# ESM_ESM_52D00000h register map
Vendor: Texas Instruments
Peripheral module from a debugger description file (folder AM261x).
Registers are 32-bit, read-write, reset 0x0 unless marked. A register's access mark holds for its fields unless they carry their own. Offsets are as the file gives them; lines under a group give offsets from that group; [hi:lo] are bit positions; {n}, {i} and the like mark numbered series; 'fields as' and 'values as' point back to an identical list; <NAME> marks a mode.

## ESM
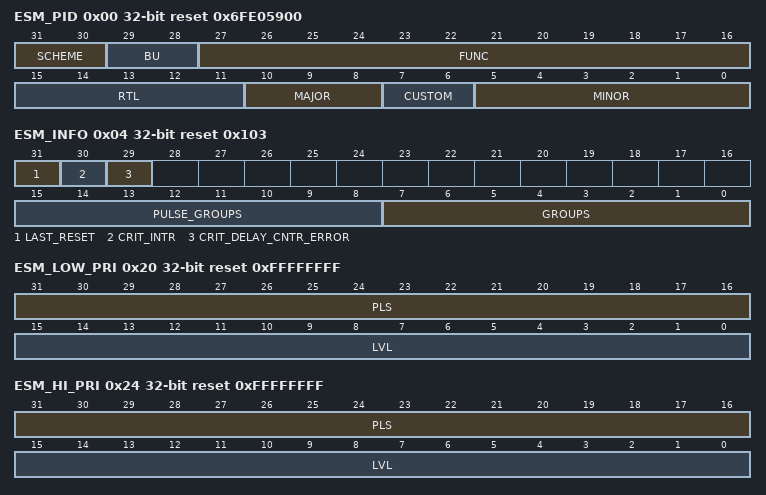
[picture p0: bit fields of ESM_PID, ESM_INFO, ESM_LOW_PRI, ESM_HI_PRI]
0x00 ESM_PID ro reset 0x6FE05900 — The Revision Register contains the major and minor revisions for the module.
  [31:30] SCHEME — PID register scheme
  [29:28] BU — Business Unit: 10 = Processors
  [27:16] FUNC — Module ID
  [15:11] RTL — RTL revision. Will vary depending on release.
  [10:8] MAJOR — Major revision
  [7:6] CUSTOM
  [5:0] MINOR — Minor revision
0x04 ESM_INFO ro reset 0x103 — The Info Register gives the configuration Inforrmation of this ESM.
  [31] LAST_RESET — Indicates the Source of the last Reset
  [30] CRIT_INTR — Indicates if the critical priority interrupt output has asserted
  [29] CRIT_DELAY_CNTR_ERROR — Indicates if a bit error has occurred in the critical priority interrupt delay counter
  [15:8] PULSE_GROUPS — Number of Pulse Error Groups
  [7:0] GROUPS — Total number of Error Groups
0x08 ESM_EN — The Global Enable Register has the master interrupt mask.
  [3:0] KEY — Global Enable
0x0C ESM_SFT_RST wo — The Global Soft Reset Register controls the global clear for raw status and enables.
  [3:0] KEY — Global Soft Reset
0x10 ESM_ERR_RAW access not given — Raw Status/Set Register for Configuration Errors.
  [2:0] STS — This is the raw status for config errors (access R/W1TS)
0x14 ESM_ERR_STS access not given — Config Error Enable and Clear Register.
  [2:0] MSK — This is the masked status/clear for config errors (access R/W1TC)
0x18 ESM_ERR_EN_SET access not given — Config Error Enable Set Register.
  [2:0] MSK — This is the mask enable set for config errors (access R/W1TS)
0x1C ESM_ERR_EN_CLR access not given — Config Error Interrupt Enabled Clear register.
  [2:0] MSK — This is the mask enable clear for config errors (access R/W1TC)
0x20 ESM_LOW_PRI ro reset 0xFFFFFFFF — Shows which is the highest priority outstanding low priority interrupt.
  [31:16] PLS — This is the highest priority outstanding low priority pulse interrupt
  [15:0] LVL — This is the highest priority outstanding low priority level interrupt
0x24 ESM_HI_PRI ro reset 0xFFFFFFFF — Shows which is the highest priority outstanding high priority interrupt.
  [31:16] PLS — This is the highest priority outstanding high priority pulse interrupt
  [15:0] LVL — This is the highest priority outstanding high priority level interrupt
0x28 ESM_LOW ro — Shows which groups have oustanding low priority interrupts.
  [31:0] STS — This is the raw status for config errors
0x2C ESM_HI ro — Shows which groups have oustanding high priority interrupts.
  [31:0] STS — This is the raw status for config errors
0x30 ESM_EOI wo — End of Interrupt Register.
  [10:0] KEY — This is the interrupt being serviced
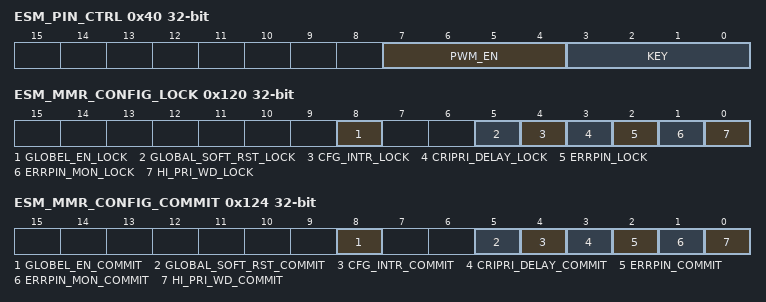
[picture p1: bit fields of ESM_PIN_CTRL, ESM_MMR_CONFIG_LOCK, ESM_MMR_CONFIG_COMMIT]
0x40 ESM_PIN_CTRL — This register controls the error_pin_n output.
  [7:4] PWM_EN — PWM enable
  [3:0] KEY — Pin Control Key
0x44 ESM_PIN_STS ro — This register reflects the status of the error_pin_n output.
  [0] VAL — Value of the error_pin_n
0x48 ESM_PIN_CNTR ro — This register shows the current value of the error pin counter.
  [23:0] COUNT — Current Counter Value
0x4C ESM_PIN_CNTR_PRE — This register contains the value that is loaded in to the Error Counter.
  [23:0] COUNT — Counter Pre-Load Value
0x50 ESM_PWMH_PIN_CNTR ro — This register shows the current value of the error pin PWM high counter.
  [23:0] COUNT — Current Counter Value
0x54 ESM_PWMH_PIN_CNTR_PRE — This register contains the value that is loaded in to the Error PWM High Counter.
  [23:0] COUNT — Counter Pre-Load Value
0x58 ESM_PWML_PIN_CNTR ro — This register shows the current value of the error pin PWM low counter.
  [23:0] COUNT — Current Counter Value
0x5C ESM_PWML_PIN_CNTR_PRE — This register contains the value that is loaded in to the Error PWM Low Counter.
  [23:0] COUNT — Counter Pre-Load Value
0x60 ESM_CRIT_DELAY_CNTR ro — This register shows the current value of the Critical Priority Interrupt Delay Counter.
  [31:0] COUNT — Current Counter Value
0x64 ESM_CRIT_DELAY_CNTR_PRE — This register contains the value that is loaded into the Critical Priority Interrupt Delay Counter.
  [31:0] COUNT — Counter Pre-Load Value
0x80 ESM_HI_PRI_WD_CFG — The High Priority Watchdog Config Register is used to enable or disable the High Priority Watchdog and its associated interrupt.
  [3:0] WD_EN — Enable field for the High Priority Watchdog. 0xA Enables the watchdog. All other values disable the watchdog
0x84 ESM_HI_PRI_WD_CNTR ro — The High Priority Watchdog Counter Register reflects the current value of the High Priority Watchdog Counter. When enabled, this counter will start decrementing (from the High Priority Pre-Load value) as soon as any of the enabled Errors associated with the High Priority Interrupt is active. This counter is reset by the warm reset.
  [31:0] COUNT — Current Counter Value
0x88 ESM_HI_PRI_WD_CNTR_PRE — The High Priority Watchdog Pre-Load Register reflects the value that is loaded into the High Priority Watchdog Counter Register.
  [31:0] COUNT — Counter Pre-Load Value
0x8C ESM_HI_PRI_WD_INTR_SET access not given — The High Priority Watchdog Status/Set Register indicates the status of the High Priority Watchdog Interrupt. This register is reset by the Power On Reset. A write to this register may allow software to set the interrupt output.
  [0] VAL — Read the current interrupt status. Write 1 to set the interrupt output (access R/W1TS)
0x90 ESM_HI_PRI_WD_INTR_CLR access not given — The High Priority Watchdog Status/Clear Register indicates the status of the High Priority Watchdog Interrupt. This register is reset by the Power On Reset. A write to this register may allow software to temporarily clear the interrupt.
  [0] VAL — Read the current interrupt status. Write 1 to clear the interrupt output. The interrupt will reassert if the conditions that triggered it persist (access R/W1TC)
0xA0 ESM_ERRPIN_MON_CFG — The Error Pin Monitor Config Register is used to enable or disable the Error Pin Monitor and its associated interrupt.
  [3:0] MON_EN — Enable field for the Error Pin Monitor. 0xA Enables the monitor. All other values disable the monitor
0xA4 ESM_ERRPIN_MON_INTR_SET access not given — The Error Pin Monitor Interrupt Status/Set Register indicates the status of the Error Pin Monitor Interrupt. This register is reset by the Power On Reset. A write to this register may allow software to set the interrupt output.
  fields as ESM_HI_PRI_WD_INTR_SET
0xA8 ESM_ERRPIN_MON_INTR_CLR access not given — The Error Pin Monitor Status/Clear Register indicates the status of the Error Pin Monitor Interrupt. This register is reset by the Power On Reset. A write to this register may allow software to temporarily clear the interrupt.
  fields as ESM_HI_PRI_WD_INTR_CLR
0x100 ESM_GROUP_N_LOCK — The fields of the Group N Interrupt Lock Register lock the configuration for the associated Error Group N Interrupt Enable Set/Clear Registers and the Error Group N Interrupt Priority Register. This locks the associated enable and priority bits for each Group for Low and High Priority Interrupts. Locks may be written until the associated Commit MMR fields are set to 1. Once Lock is 1 and Commit is 1, the associated configuration may not be changed until reset.
  [31:0] LOCK — Each bit lock[N] bit will lock the associated masking MMRs associated with Group N. These are: Error Group N Interrupt Enabled Set Register, Error Group N Interrupt Enabled Clear Register, Error Group N Interrupt Priority Register
0x104 ESM_GROUP_N_COMMIT — The fields of the Group N Interrupt Commit Register commit the lock configuration for the associated Group N Interrupt Lock Register. This prevents the Locks in the Group N Interrupt Lock Register from changing. Once Commit is 1, the associated Lock and Commit may not be changed until reset.
  [31:0] COMMIT — Each bit commit[N] bit will commit the lock configuration for the corresponding bit in the Group N Interrupt Lock Register.
0x110 ESM_ERR_PIN_INFLUENCE_LOCK — The fields of the Error Pin Influence Lock Register lock the Error Pin Influence configuration for the associated Error Groups. Locks may be written until the associated Commit MMR fields are set to 1. Once Lock is 1 and Commit is 1, the associated configuration may not be changed until reset.
  [31:0] LOCK — Each bit lock[N] bit will lock the associated masking MMRs associated with Group N. These are: Error Group N Error Pin Influence Set Register, Error Group N Error Pin Influence Clear Register
0x114 ESM_ERR_PIN_INFLUENCE_COMMIT — The fields of the Error Pin Influence Commit Register commit the lock configuration for the associated Error Groups. This prevents the Locks in the Error Pin Influence Lock Register from changing. Once Commit is 1, the associated Lock and Commit may not be changed until reset.
  [31:0] COMMIT — Each bit commit[N] bit will commit the lock configuration for the corresponding bit in the Error Pin Influence Lock Register.
0x118 ESM_CRI_PRI_INFLUENCE_LOCK — The fields of the Critical Priority Interrupt Influence Lock Register lock the Critical Priority Interrupt Influence configuration for the associated Error Groups. Locks may be written until the associated Commit MMR fields are set to 1. Once Lock is 1 and Commit is 1, the associated configuration may not be changed until reset.
  [31:0] LOCK — Each bit lock[N] bit will lock the associated masking MMRs associated with Group N. These are: Error Group N Critical Priority Interrupt Influence Set Register, Error Group N Critical Priority Interrupt Influence Clear Register
0x11C ESM_CRI_PRI_INFLUENCE_COMMIT — The fields of the Critical Priority Interrupt Influence Commit Register commit the lock configuration for the associated Error Groups. This prevents the Locks in the Critical Priority Interrupt Influence Lock Register from changing. Once Commit is 1, the associated Lock and Commit may not be changed until reset.
  [31:0] COMMIT — Each bit commit[N] bit will commit the lock configuration for the corresponding bit in the Critical Priority Interrupt Influence Lock Register.
0x120 ESM_MMR_CONFIG_LOCK — The fields of the MMR Config Lock Register lock the configuration for the associated MMRs. This prevents changes once the lock configuration is committed with the MMR Config Commit Register. Locks may be written until the associated Commit MMR fields are set to 1. Once Lock is 1 and Commit is 1, the associated configuration may not be changed until reset.
  [8] GLOBEL_EN_LOCK — Locks the Global Enable Register.
  [5] GLOBAL_SOFT_RST_LOCK — Locks the Global Soft Reset Register.
  [4] CFG_INTR_LOCK — Locks the Config Error Interrupt registers. These are: Config Error Interrupt Enabled Set Register, Config Error Interrupt Enabled Clear Register
  [3] CRIPRI_DELAY_LOCK — Locks the Critical Priority Interrupt Delay Counter Pre-Load Register.
  [2] ERRPIN_LOCK — Locks the Error Pin configuration registers. These are: Error Pin Control Register, Error Pin Counter Pre-Load Register, Error Pin PWM High Counter Pre-Load Register, Error Pin PWM Low Counter Pre-Load Register
  [1] ERRPIN_MON_LOCK — Locks the Error Pin Monitor Config Register.
  [0] HI_PRI_WD_LOCK — Locks the High Priority Watchdog configuration registers. These are: High Priority Watchdog Config Register, High Priority Watchdog Pre-Load Register.
0x124 ESM_MMR_CONFIG_COMMIT — The fields of the MMR Config Commit Register commit the lock configuration for the associated MMR Config Lock MMR bits. This prevents the Locks in the MMR Config Lock Register from changing. Once Commit is 1, the associated Lock and Commit may not be changed until reset.
  [8] GLOBEL_EN_COMMIT — Commits the lock for the Global Enable Register.
  [5] GLOBAL_SOFT_RST_COMMIT — Commits the lock for the Global Soft Reset Register.
  [4] CFG_INTR_COMMIT — Commits the lock for the Config Error Interrupt registers. These are: Config Error Interrupt Enabled Set Register, Config Error Interrupt Enabled Clear Register
  [3] CRIPRI_DELAY_COMMIT — Commits the lock for the Critical Priority Interrupt Delay Counter Pre-Load Register.
  [2] ERRPIN_COMMIT — Commits the lock for the Error Pin configuration registers. These are: Error Pin Control Register, Error Pin Counter Pre-Load Register, Error Pin PWM High Counter Pre-Load Register, Error Pin PWM Low Counter Pre-Load Register
  [1] ERRPIN_MON_COMMIT — Commits the lock for the Error Pin Monitor Config Register.
  [0] HI_PRI_WD_COMMIT — Commits the lock for the High Priority Watchdog configuration registers. These are: High Priority Watchdog Config Register, High Priority Watchdog Pre-Load Register.
0x400 ESM_PCR_GENERATED_MEMORY_MAP_ERR_GRP_RAW_j access not given — Raw Status/Set Register for Group A Errors
  [31:0] STS — This is the raw status/set for errors Group A (access R/W1TS)
0x404 ESM_PCR_GENERATED_MEMORY_MAP_ERR_GRP_STS_j access not given — Error Enable and Clear Register
  [31:0] MSK — This is the masked status/clear for errors in Group A (access R/W1TC)
0x408 ESM_PCR_GENERATED_MEMORY_MAP_ERR_GRP_INTR_EN_SET_j access not given — Level Error Enable Set Register
  [31:0] MSK — This is the mask enable set for errors in Group A (access R/W1TS)
0x40C ESM_PCR_GENERATED_MEMORY_MAP_ERR_GRP_INTR_EN_CLR_j access not given — Level Error Interrupt Enabled Clear register
  [31:0] MSK — This is the mask enable clear for errors in Group A (access R/W1TC)
0x410 ESM_PCR_GENERATED_MEMORY_MAP_ERR_GRP_INT_PRIO_j — Level Error Interrupt Priority register
  [31:0] MSK — This is interrupt priority for errors in Group A
0x414 ESM_PCR_GENERATED_MEMORY_MAP_ERR_GRP_PIN_EN_SET_j access not given — Error Pin Enabled Set register
  [31:0] MSK — This is the error pin influence enable set for errors in Group A (access R/W1TS)
0x418 ESM_PCR_GENERATED_MEMORY_MAP_ERR_GRP_PIN_EN_CLR_j access not given — Error Pin Enabled Clear register
  [31:0] MSK — This is the error pin influence enable clear for errors in Group A (access R/W1TC)
0x800 ESM_PCR_GENERATED_MEMORY_MAP_ERR_EXT_GRP_CRIT_EN_SET_j access not given — Level Critical Priority Interrupt Enabled Clear register
  [31:0] MSK — This is the critical priority interrupt influence enable set for errors in Group A (access R/W1TS)
0x804 ESM_PCR_GENERATED_MEMORY_MAP_ERR_EXT_GRP_CRIT_EN_CLR_j access not given — Level Critical Priority Interrupt Enabled Clear register
  [31:0] MSK — This is the critical priority interrupt influence enable clear for errors in Group A (access R/W1TC)
